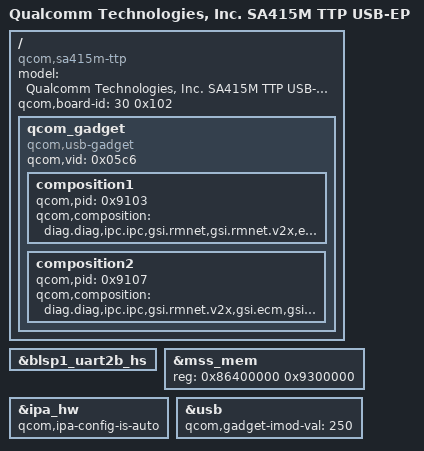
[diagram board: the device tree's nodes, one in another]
/* Copyright (c) 2017-2020, The Linux Foundation. All rights reserved.
 *
 * This program is free software; you can redistribute it and/or modify
 * it under the terms of the GNU General Public License version 2 and
 * only version 2 as published by the Free Software Foundation.
 *
 * This program is distributed in the hope that it will be useful,
 * but WITHOUT ANY WARRANTY; without even the implied warranty of
 * MERCHANTABILITY or FITNESS FOR A PARTICULAR PURPOSE.  See the
 * GNU General Public License for more details.
 */

/dts-v1/;

#include "sa415m-ttp.dtsi"
#include "sdxpoorwills-v2.dtsi"

/ {
	model = "Qualcomm Technologies, Inc. SA415M TTP USB-EP";
	compatible = "qcom,sa415m-ttp",
		"qcom,sdxpoorwills", "qcom,ttp";
	qcom,board-id = <30 0x102>;

	qcom_gadget {
		compatible = "qcom,usb-gadget";
		qcom,vid = <0x05c6>;

		composition1 {
			qcom,pid = <0x9103>;
			qcom,composition = "diag.diag,ipc.ipc,gsi.rmnet,gsi.rmnet.v2x,ecm.ecm,gsi.dpl";
		};

		composition2 {
			qcom,pid = <0x9107>;
			qcom,composition = "diag.diag,ipc.ipc,gsi.rmnet.v2x,gsi.ecm,gsi.dpl";
		};
	};
};

&blsp1_uart2b_hs {
	status = "okay";
};

&mss_mem {
	reg = <0x86400000 0x9300000>;
};

&ipa_hw {
	qcom,ipa-config-is-auto;
};

&usb {
	qcom,gadget-imod-val = <250>;
};
